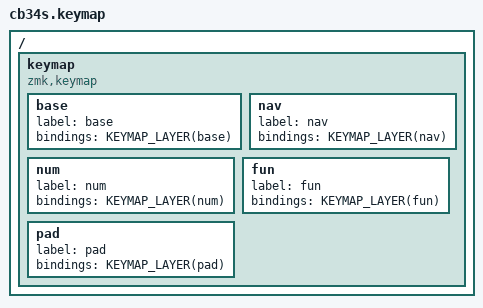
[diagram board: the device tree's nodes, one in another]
/*
 * cb34s — thin keymap.
 *
 * All content lives in config/shared/. This file only selects the board geometry
 * adapter and lays the shared master layers onto it. cb34s is a pure 3x5+2 core,
 * so it now uses the original TOTEM content unchanged (the consolidation goal).
 * To change a key, combo, macro or HRM, edit config/shared/*, never this file.
 */

#include <behaviors.dtsi>
#include <dt-bindings/zmk/keys.h>
#include <dt-bindings/zmk/bt.h>
#include <dt-bindings/zmk/outputs.h>

#include "geometry/geom_3x5_2.h"

#include "shared/keys_de.h"
#include "shared/settings.dtsi"
#include "shared/behaviors.dtsi"
#include "shared/macros.dtsi"
#include "shared/combos.dtsi"
#include "shared/core_blocks.dtsi"

/ {
    keymap {
        compatible = "zmk,keymap";

        base { label = "base"; bindings = <KEYMAP_LAYER(base)>; };
        nav  { label = "nav";  bindings = <KEYMAP_LAYER(nav)>;  };
        num  { label = "num";  bindings = <KEYMAP_LAYER(num)>;  };
        fun  { label = "fun";  bindings = <KEYMAP_LAYER(fun)>;  };
        pad  { label = "pad";  bindings = <KEYMAP_LAYER(pad)>;  };
    };
};
